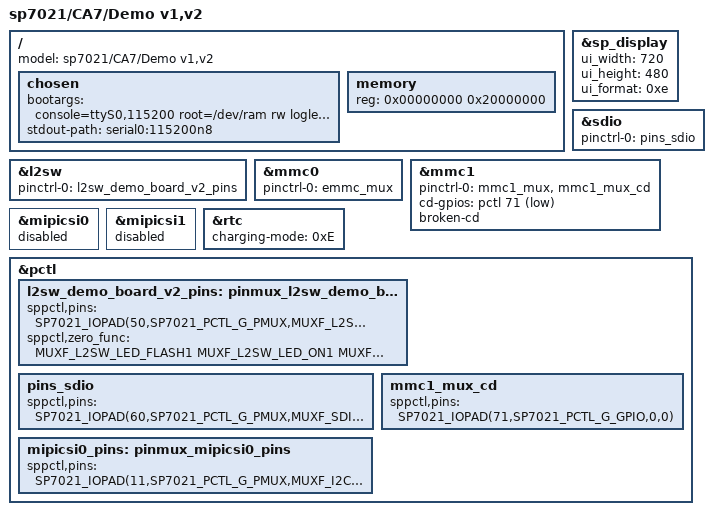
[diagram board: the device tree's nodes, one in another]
/dts-v1/;

#include "sp7021-ChipC.dtsi"

/ {
	model = "sp7021/CA7/Demo v1,v2";

	chosen {
		bootargs = "console=ttyS0,115200 root=/dev/ram rw loglevel=8 earlyprintk";
		stdout-path = "serial0:115200n8";
	};

	memory {
		reg = <0x00000000 0x20000000>; /* 512MB */
	};
};

&sp_display {
	ui_width = <720>;
	ui_height = <480>;
	ui_format = <0xe>;
		/* 0x2 = 8bpp (ARGB)
		 * 0x4 = YUY2
		 * 0x8 = RGB565
		 * 0x9 = ARGB1555
		 * 0xa = RGBA4444
		 * 0xb = ARGB4444
		 * 0xd = RGBA8888
		 * 0xe = ARGB8888 */
};

&sdio {
	pinctrl-names = "default";
	pinctrl-0 = <&pins_sdio>;
};

&l2sw {
	pinctrl-names = "default";
	pinctrl-0 = <&l2sw_demo_board_v2_pins>;
};

&mmc0 {
	pinctrl-names = "default";
	pinctrl-0 = <&emmc_mux>;
};

&mmc1 {
	pinctrl-names = "default";
	pinctrl-0 = <&mmc1_mux &mmc1_mux_cd>;
	cd-gpios = <&pctl 71 GPIO_ACTIVE_LOW>;
	broken-cd;
};

&mipicsi0 {
	status = "disabled";
};

&mipicsi1 {
	status = "disabled";
};

&rtc {
	charging-mode = <0xE>;
	/*
	 *      0xE     Disable
	 *      0x1     0.86mA (2K Ohm with diode)
	 *      0x5     1.81mA (250 Ohm with diode)
	 *      0x9     2.07mA (50 Ohm with diode)
	 *      0xD     16.0mA (0 Ohm with diode)
	 *      0x3     1.36mA (2K Ohm without diode)
	 *      0x7     3.99mA (250 Ohm without diode)
	 *      0xB     4.41mA (50 Ohm without diode)
	 *      0xF     16.0mA (0 Ohm without diode)    */
};

&pctl {
	pinctrl-names = "default";

	l2sw_demo_board_v2_pins: pinmux_l2sw_demo_board_v2_pins {
		sppctl,pins = <
			SP7021_IOPAD(50,SP7021_PCTL_G_PMUX,MUXF_L2SW_CLK_OUT,0)
			SP7021_IOPAD(44,SP7021_PCTL_G_PMUX,MUXF_L2SW_MAC_SMI_MDC,0)
			SP7021_IOPAD(54,SP7021_PCTL_G_PMUX,MUXF_L2SW_LED_FLASH0,0)
			SP7021_IOPAD(45,SP7021_PCTL_G_PMUX,MUXF_L2SW_LED_ON0,0)
			SP7021_IOPAD(43,SP7021_PCTL_G_PMUX,MUXF_L2SW_MAC_SMI_MDIO,0)
			SP7021_IOPAD(53,SP7021_PCTL_G_PMUX,MUXF_L2SW_P0_MAC_RMII_TXEN,0)
			SP7021_IOPAD(51,SP7021_PCTL_G_PMUX,MUXF_L2SW_P0_MAC_RMII_TXD0,0)
			SP7021_IOPAD(52,SP7021_PCTL_G_PMUX,MUXF_L2SW_P0_MAC_RMII_TXD1,0)
			SP7021_IOPAD(47,SP7021_PCTL_G_PMUX,MUXF_L2SW_P0_MAC_RMII_CRSDV,0)
			SP7021_IOPAD(48,SP7021_PCTL_G_PMUX,MUXF_L2SW_P0_MAC_RMII_RXD0,0)
			SP7021_IOPAD(49,SP7021_PCTL_G_PMUX,MUXF_L2SW_P0_MAC_RMII_RXD1,0)
			SP7021_IOPAD(46,SP7021_PCTL_G_PMUX,MUXF_L2SW_P0_MAC_RMII_RXER,0)
		>;
		sppctl,zero_func = <
			MUXF_L2SW_LED_FLASH1
			MUXF_L2SW_LED_ON1
			MUXF_L2SW_P1_MAC_RMII_TXEN
			MUXF_L2SW_P1_MAC_RMII_TXD0
			MUXF_L2SW_P1_MAC_RMII_TXD1
			MUXF_L2SW_P1_MAC_RMII_CRSDV
			MUXF_L2SW_P1_MAC_RMII_RXD0
			MUXF_L2SW_P1_MAC_RMII_RXD1
			MUXF_L2SW_P1_MAC_RMII_RXER
			MUXF_DAISY_MODE
		>;
	};

	// SDIO for RTL8189ETV
	pins_sdio: pins_sdio {
		sppctl,pins = <
			SP7021_IOPAD(60,SP7021_PCTL_G_PMUX,MUXF_SDIO_D1,0)
			SP7021_IOPAD(58,SP7021_PCTL_G_PMUX,MUXF_SDIO_D0,0)
			SP7021_IOPAD(57,SP7021_PCTL_G_PMUX,MUXF_SDIO_CLK,0)
			SP7021_IOPAD(62,SP7021_PCTL_G_PMUX,MUXF_SDIO_CMD,0)
			SP7021_IOPAD(64,SP7021_PCTL_G_PMUX,MUXF_SDIO_D3,0)
			SP7021_IOPAD(59,SP7021_PCTL_G_PMUX,MUXF_SDIO_D2,0)
		>;
	};

	mmc1_mux_cd: mmc1_mux_cd {
		sppctl,pins = < SP7021_IOPAD(71,SP7021_PCTL_G_GPIO,0,0) >;
	};

	mipicsi0_pins: pinmux_mipicsi0_pins {
		sppctl,pins = <
			SP7021_IOPAD(11,SP7021_PCTL_G_PMUX,MUXF_I2CM1_DAT,0)
			SP7021_IOPAD(12,SP7021_PCTL_G_PMUX,MUXF_I2CM1_CLK,0)
		>;
	};
};
